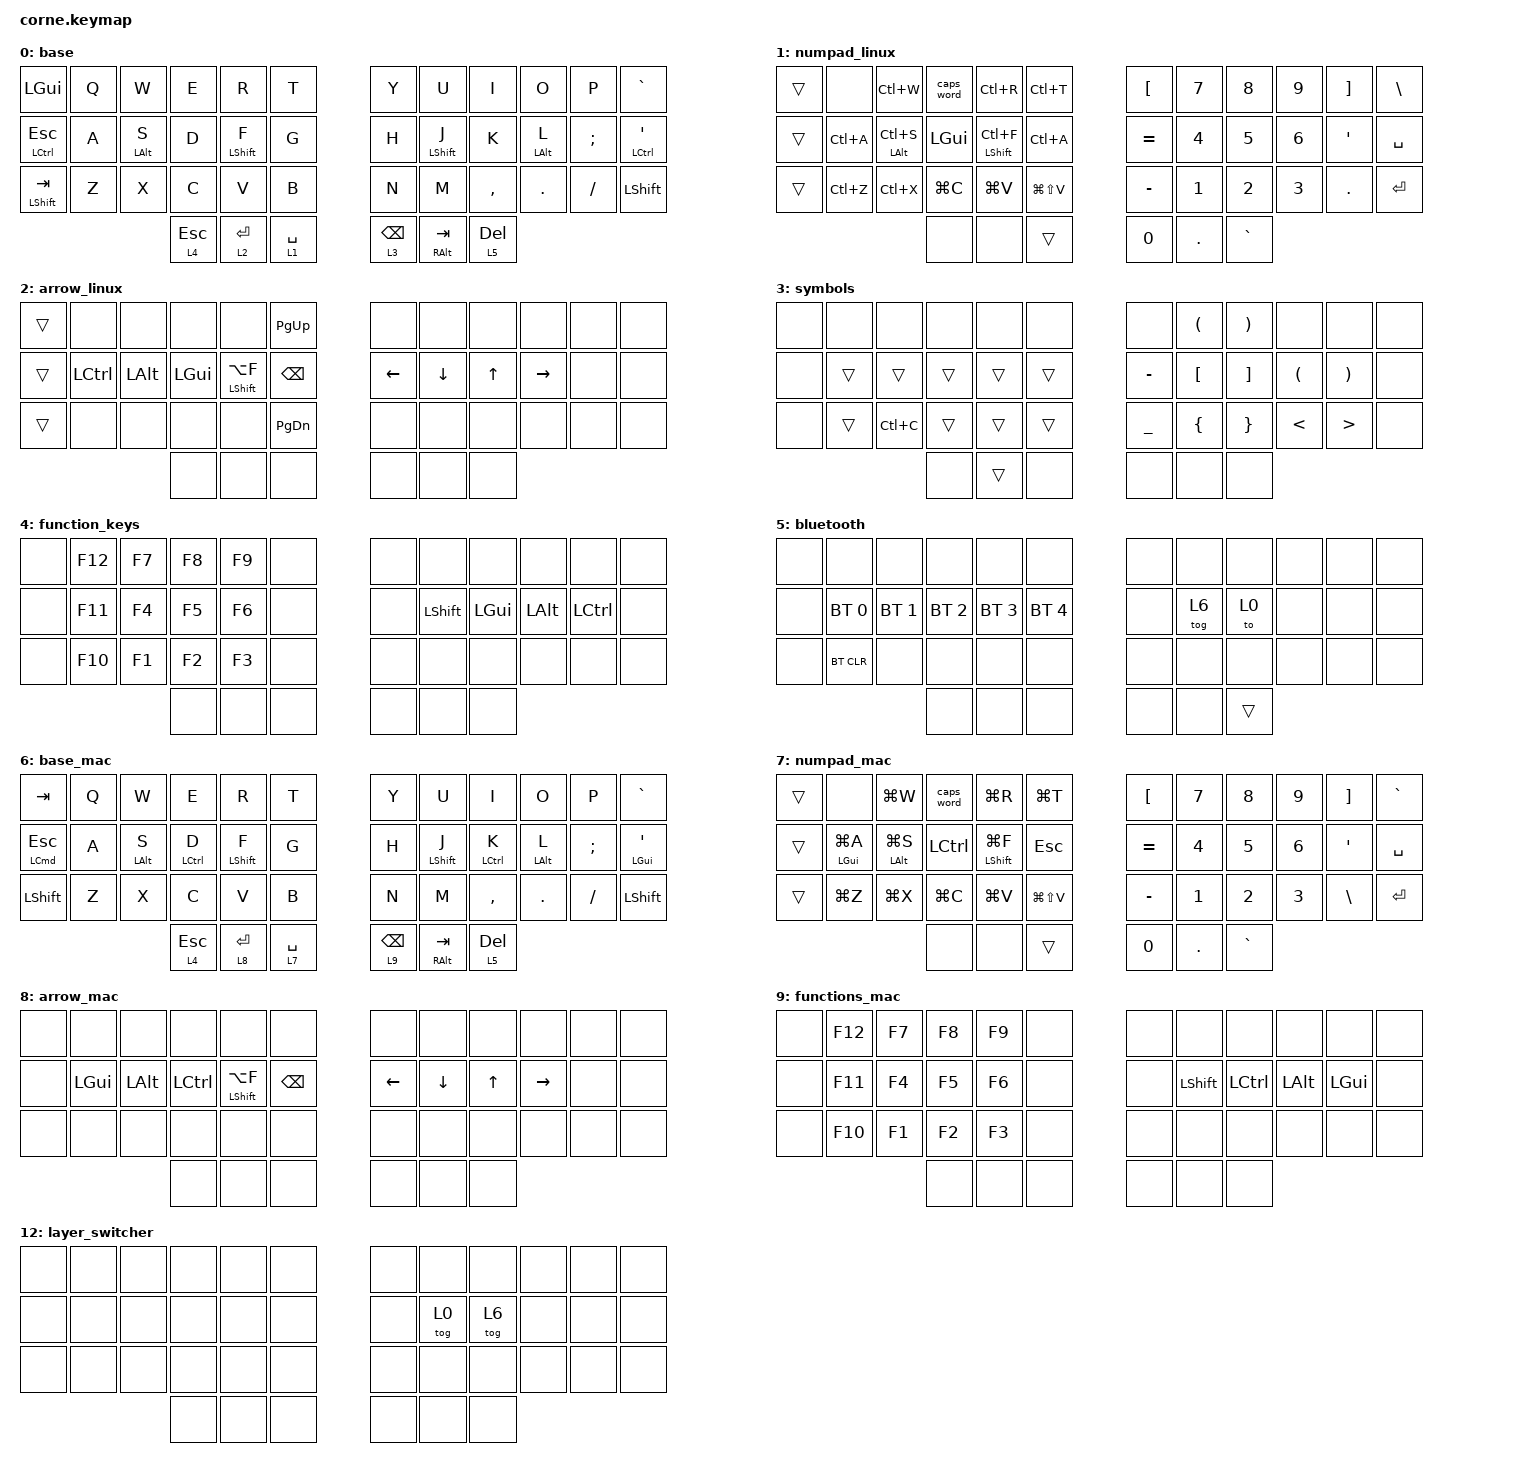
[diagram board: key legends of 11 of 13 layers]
/*
 * Copyright (c) 2020 The ZMK Contributors
 *
 * SPDX-License-Identifier: MIT
 */

#include <behaviors.dtsi>
#include <dt-bindings/zmk/bt.h>
#include <dt-bindings/zmk/keys.h>

&mt {
    flavor = "balanced";
    tapping-term-ms = <150>;
};

&lt { flavor = "hold-preferred"; };

/ {
    keymap {
        compatible = "zmk,keymap";

        base {
            // -----------------------------------------------------------------------------------------
            // |  TAB |  Q  |  W  |  E  |  R  |  T  |   |  Y  |  U   |  I  |  O  |  P  | BKSP |
            // | CTRL |  A  |  S  |  D  |  F  |  G  |   |  H  |  J   |  K  |  L  |  ;  |  '   |
            // | SHFT |  Z  |  X  |  C  |  V  |  B  |   |  N  |  M   |  ,  |  .  |  /  | ESC  |
            //                    | GUI | LWR | SPC |   | ENT | RSE  | ALT |

            bindings = <
&kp LGUI            &kp Q  &kp W       &kp E      &kp R             &kp T          &kp Y            &kp U             &kp I         &kp O           &kp P     &kp GRAVE
&mt LCTRL ESC       &kp A  &mt LALT S  &kp D      &mt LEFT_SHIFT F  &kp G          &kp H            &mt LEFT_SHIFT J  &kp K         &mt LEFT_ALT L  &kp SEMI  &mt LCTRL SINGLE_QUOTE
&mt LEFT_SHIFT TAB  &kp Z  &kp X       &kp C      &kp V             &kp B          &kp N            &kp M             &kp COMMA     &kp DOT         &kp FSLH  &kp LEFT_SHIFT
                                       &lt 4 ESC  &lt 2 ENTER       &lt 1 SPACE    &lt 3 BACKSPACE  &mt RALT TAB      &lt 5 DELETE
            >;
        };

        numpad_linux {
            bindings = <
&trans  &none      &kp LC(W)       &caps_word  &kp LC(R)             &kp LC(T)        &kp LBKT   &kp N7   &kp N8     &kp N9  &kp RBKT    &kp BACKSLASH
&trans  &kp LC(A)  &mt LALT LC(S)  &kp LGUI    &mt LEFT_SHIFT LC(F)  &kp LC(A)        &kp EQUAL  &kp N4   &kp N5     &kp N6  &kp SQT     &kp SPACE
&trans  &kp LC(Z)  &kp LC(X)       &kp LG(C)   &kp LG(V)             &kp LG(LS(V))    &kp MINUS  &kp N1   &kp N2     &kp N3  &kp PERIOD  &kp ENTER
                                   &none       &none                 &trans           &kp N0     &kp DOT  &kp GRAVE
            >;
        };

        arrow_linux {
            bindings = <
&trans  &none      &none     &none     &none                 &kp PG_UP        &none     &none     &none   &none      &none  &none
&trans  &kp LCTRL  &kp LALT  &kp LGUI  &mt LEFT_SHIFT LA(F)  &kp BSPC         &kp LEFT  &kp DOWN  &kp UP  &kp RIGHT  &none  &none
&trans  &none      &none     &none     &none                 &kp PAGE_DOWN    &none     &none     &none   &none      &none  &none
                             &none     &none                 &none            &none     &none     &none
            >;
        };

        symbols {
            // -----------------------------------------------------------------------------------------
            // |  TAB |  1  |  2  |  3  |  4  |  5  |   |  6  |  7  |  8  |  9  |  0  | BKSP |
            // | BTCLR| BT1 | BT2 | BT3 | BT4 | BT5 |   | LFT | DWN |  UP | RGT |     |      |
            // | SHFT |     |     |     |     |     |   |     |     |     |     |     |      |
            //                    | GUI |     | SPC |   | ENT |     | ALT |

            bindings = <
&none  &none   &none      &none   &none   &none     &none      &kp LEFT_PARENTHESIS  &kp RIGHT_PARENTHESIS  &none                 &none                  &none
&none  &trans  &trans     &trans  &trans  &trans    &kp MINUS  &kp LEFT_BRACKET      &kp RIGHT_BRACKET      &kp LEFT_PARENTHESIS  &kp RIGHT_PARENTHESIS  &none
&none  &trans  &kp LC(C)  &trans  &trans  &trans    &kp UNDER  &kp LEFT_BRACE        &kp RIGHT_BRACE        &kp LT                &kp GT                 &none
                          &none   &trans  &none     &none      &none                 &none
            >;
        };

        function_keys {
            bindings = <
&none  &kp F12  &kp F7  &kp F8  &kp F9  &none    &none  &none           &none     &none     &none             &none
&none  &kp F11  &kp F4  &kp F5  &kp F6  &none    &none  &kp LEFT_SHIFT  &kp LGUI  &kp LALT  &kp LEFT_CONTROL  &none
&none  &kp F10  &kp F1  &kp F2  &kp F3  &none    &none  &none           &none     &none     &none             &none
                        &none   &none   &none    &none  &none           &none
            >;
        };

        bluetooth {
            bindings = <
&none  &none         &none         &none         &none         &none           &none  &none   &none   &none  &none  &none
&none  &bt BT_SEL 0  &bt BT_SEL 1  &bt BT_SEL 2  &bt BT_SEL 3  &bt BT_SEL 4    &none  &tog 6  &to 0   &none  &none  &none
&none  &bt BT_CLR    &none         &none         &none         &none           &none  &none   &none   &none  &none  &none
                                   &none         &none         &none           &none  &none   &trans
            >;
        };

        base_mac {
            bindings = <
&kp TAB               &kp Q  &kp W       &kp E        &kp R             &kp T          &kp Y            &kp U             &kp I         &kp O           &kp P     &kp GRAVE
&mt LEFT_COMMAND ESC  &kp A  &mt LALT S  &mt LCTRL D  &mt LEFT_SHIFT F  &kp G          &kp H            &mt LEFT_SHIFT J  &mt LCTRL K   &mt LEFT_ALT L  &kp SEMI  &mt LEFT_GUI SINGLE_QUOTE
&kp LEFT_SHIFT        &kp Z  &kp X       &kp C        &kp V             &kp B          &kp N            &kp M             &kp COMMA     &kp DOT         &kp FSLH  &kp LEFT_SHIFT
                                         &lt 4 ESC    &lt 8 ENTER       &lt 7 SPACE    &lt 9 BACKSPACE  &mt RALT TAB      &lt 5 DELETE
            >;
        };

        numpad_mac {
            bindings = <
&trans  &none           &kp LG(W)       &caps_word  &kp LG(R)             &kp LG(T)        &kp LBKT   &kp N7   &kp N8     &kp N9  &kp RBKT  &kp GRAVE
&trans  &mt LGUI LG(A)  &mt LALT LG(S)  &kp LCTRL   &mt LEFT_SHIFT LG(F)  &kp ESC          &kp EQUAL  &kp N4   &kp N5     &kp N6  &kp SQT   &kp SPACE
&trans  &kp LG(Z)       &kp LG(X)       &kp LG(C)   &kp LG(V)             &kp LG(LS(V))    &kp MINUS  &kp N1   &kp N2     &kp N3  &kp BSLH  &kp ENTER
                                        &none       &none                 &trans           &kp N0     &kp DOT  &kp GRAVE
            >;
        };

        arrow_mac {
            bindings = <
&none  &none     &none     &none      &none                 &none       &none     &none     &none   &none      &none  &none
&none  &kp LGUI  &kp LALT  &kp LCTRL  &mt LEFT_SHIFT LA(F)  &kp BSPC    &kp LEFT  &kp DOWN  &kp UP  &kp RIGHT  &none  &none
&none  &none     &none     &none      &none                 &none       &none     &none     &none   &none      &none  &none
                           &none      &none                 &none       &none     &none     &none
            >;
        };

        functions_mac {
            bindings = <
&none  &kp F12  &kp F7  &kp F8  &kp F9  &none    &none  &none           &none      &none     &none         &none
&none  &kp F11  &kp F4  &kp F5  &kp F6  &none    &none  &kp LEFT_SHIFT  &kp LCTRL  &kp LALT  &kp LEFT_GUI  &none
&none  &kp F10  &kp F1  &kp F2  &kp F3  &none    &none  &none           &none      &none     &none         &none
                        &none   &none   &none    &none  &none           &none
            >;
        };

        Hyper {
            bindings = <
&none  &none  &none  &none                  &none                  &none    &none                     &none                     &none                   &none                      &none  &none
&none  &none  &none  &kp LS(LA(LC(LG(D))))  &kp LS(LA(LC(LG(F))))  &none    &kp LS(LA(LC(LG(LEFT))))  &kp LS(LA(LG(LC(DOWN))))  &kp LS(LA(LC(LG(UP))))  &kp LS(LA(LC(LG(RIGHT))))  &none  &none
&none  &none  &none  &none                  &none                  &none    &none                     &none                     &none                   &none                      &none  &none
                     &none                  &none                  &none    &none                     &none                     &none
            >;
        };

        win-manager {
            bindings = <
&none  &none  &none  &none  &none                  &none    &none  &none  &none  &none  &none  &none
&none  &none  &none  &none  &kp LS(LA(LC(LG(F))))  &none    &none  &none  &none  &none  &none  &none
&none  &none  &none  &none  &none                  &none    &none  &none  &none  &none  &none  &none
                     &none  &none                  &none    &none  &none  &none
            >;
        };

        layer_switcher {
            bindings = <
&none  &none  &none  &none  &none  &none    &none  &none   &none   &none  &none  &none
&none  &none  &none  &none  &none  &none    &none  &tog 0  &tog 6  &none  &none  &none
&none  &none  &none  &none  &none  &none    &none  &none   &none   &none  &none  &none
                     &none  &none  &none    &none  &none   &none
            >;
        };
    };
};
